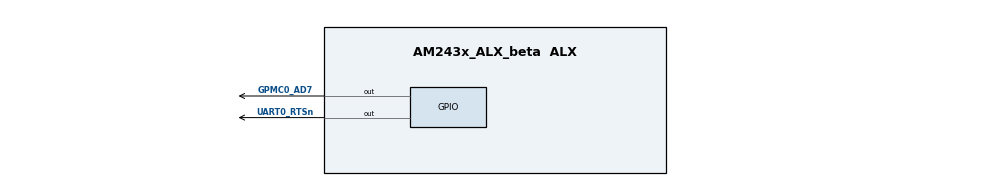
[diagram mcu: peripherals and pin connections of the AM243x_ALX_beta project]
/**
 * @cliArgs --device "AM243x_ALX_beta" --package "ALX" --part "ALX" --context "r5fss0-0" --product "MCU_PLUS_SDK@07.03.01"
 * @versions {"tool":"1.14.0+2667"}
 */

/**
 * Import the modules used in this configuration.
 */
const eeprom     = scripting.addModule("/board/eeprom/eeprom", {}, false);
const eeprom1    = eeprom.addInstance();
const flash      = scripting.addModule("/board/flash/flash", {}, false);
const flash1     = flash.addInstance();
const led        = scripting.addModule("/board/led/led", {}, false);
const led1       = led.addInstance();
const led2       = led.addInstance();
const led3       = led.addInstance();
const gpio       = scripting.addModule("/drivers/gpio/gpio", {}, false);
const gpio1      = gpio.addInstance();
const gpio2      = gpio.addInstance();
const i2c        = scripting.addModule("/drivers/i2c/i2c", {}, false);
const i2c1       = i2c.addInstance();
const pruicss    = scripting.addModule("/drivers/pruicss/pruicss", {}, false);
const pruicss1   = pruicss.addInstance();
const ethercat   = scripting.addModule("/industrial_comms/ethercat/ethercat", {}, false);
const ethercat1  = ethercat.addInstance();
const debug_log  = scripting.addModule("/kernel/dpl/debug_log");
const mpu_armv7  = scripting.addModule("/kernel/dpl/mpu_armv7", {}, false);
const mpu_armv71 = mpu_armv7.addInstance();
const mpu_armv72 = mpu_armv7.addInstance();
const mpu_armv73 = mpu_armv7.addInstance();
const mpu_armv74 = mpu_armv7.addInstance();

/**
 * Write custom configuration values to the imported modules.
 */
eeprom1.$name = "CONFIG_EEPROM0";

flash1.$name                              = "CONFIG_FLASH0";
flash1.peripheralDriver.$name             = "CONFIG_OSPI0";
flash1.peripheralDriver.OSPI.$assign      = "OSPI0";
flash1.peripheralDriver.OSPI.CLK.$assign  = "OSPI0_CLK";
flash1.peripheralDriver.OSPI.CSn0.$assign = "OSPI0_CSn0";
flash1.peripheralDriver.OSPI.D3.$assign   = "OSPI0_D3";
flash1.peripheralDriver.OSPI.D2.$assign   = "OSPI0_D2";
flash1.peripheralDriver.OSPI.D1.$assign   = "OSPI0_D1";
flash1.peripheralDriver.OSPI.D0.$assign   = "OSPI0_D0";

led1.$name = "CONFIG_LED_DIGITAL_OUTPUT";
led1.name  = "TPIC2810";

led2.$name = "CONFIG_LED_RUN";

led3.ioIndex = 16;
led3.$name   = "CONFIG_LED_ERROR";

gpio1.$name                = "CONFIG_GPIO0";
gpio1.pinDir               = "OUTPUT";
led2.peripheralDriver      = gpio1;
gpio1.GPIO.$assign         = "GPIO0";
gpio1.GPIO.gpioPin.$assign = "GPMC0_AD7";

gpio2.$name                = "CONFIG_GPIO1";
led3.peripheralDriver      = gpio2;
gpio2.GPIO.gpioPin.$assign = "UART0_RTSn";

led1.peripheralDriver    = i2c1;
i2c1.$name               = "CONFIG_I2C0";
eeprom1.peripheralDriver = i2c1;
i2c1.I2C.$assign         = "I2C0";
i2c1.I2C.SCL.$assign     = "I2C0_SCL";
i2c1.I2C.SDA.$assign     = "I2C0_SDA";

ethercat1.$name              = "CONFIG_ETHERCAT0";
ethercat1.instance           = "ICSSG1";
ethercat1.ethphy[0].$name    = "CONFIG_ETHPHY0";
ethercat1.ethphy[0].mdioPort = 3;
ethercat1.ethphy[1].$name    = "CONFIG_ETHPHY1";

ethercat1.icss                           = pruicss1;
pruicss1.$name                           = "CONFIG_PRU_ICSS1";
pruicss1.AdditionalICSSSettings[0].$name = "CONFIG_PRU_ICSS_IO0";

debug_log.enableUartLog            = true;
debug_log.enableCssLog             = false;
debug_log.uartLog.$name            = "CONFIG_UART0";
debug_log.uartLog.UART.$assign     = "USART0";
debug_log.uartLog.UART.RXD.$assign = "UART0_RXD";
debug_log.uartLog.UART.TXD.$assign = "UART0_TXD";

mpu_armv71.$name             = "CONFIG_MPU_REGION0";
mpu_armv71.size              = 31;
mpu_armv71.attributes        = "Device";
mpu_armv71.accessPermissions = "Supervisor RD+WR, User RD";
mpu_armv71.allowExecute      = false;

mpu_armv72.$name             = "CONFIG_MPU_REGION1";
mpu_armv72.size              = 15;
mpu_armv72.accessPermissions = "Supervisor RD+WR, User RD";

mpu_armv73.$name             = "CONFIG_MPU_REGION2";
mpu_armv73.baseAddr          = 0x41010000;
mpu_armv73.size              = 15;
mpu_armv73.accessPermissions = "Supervisor RD+WR, User RD";

mpu_armv74.$name             = "CONFIG_MPU_REGION3";
mpu_armv74.accessPermissions = "Supervisor RD+WR, User RD";
mpu_armv74.baseAddr          = 0x70000000;
mpu_armv74.size              = 21;

/**
 * Pinmux solution for unlocked pins/peripherals. This ensures that minor changes to the automatic solver in a future
 * version of the tool will not impact the pinmux you originally saw.  These lines can be completely deleted in order to
 * re-solve from scratch.
 */
gpio2.GPIO.$suggestSolution                                  = "GPIO1";
ethercat1.PRU_ICSSG1_MDIO.$suggestSolution                   = "PRU_ICSSG1_MDIO0";
ethercat1.PRU_ICSSG1_MDIO.MDC.$suggestSolution               = "PRG1_MDIO0_MDC";
ethercat1.PRU_ICSSG1_MDIO.MDIO.$suggestSolution              = "PRG1_MDIO0_MDIO";
ethercat1.PRU_ICSSG1_IEP.$suggestSolution                    = "PRU_ICSSG1_IEP0";
ethercat1.PRU_ICSSG1_IEP.EDC_LATCH_IN0.$suggestSolution      = "PRG1_PRU0_GPO18";
ethercat1.PRU_ICSSG1_IEP.EDC_LATCH_IN1.$suggestSolution      = "PRG1_PRU0_GPO7";
ethercat1.PRU_ICSSG1_IEP.EDC_SYNC_OUT0.$suggestSolution      = "PRG1_PRU0_GPO19";
ethercat1.PRU_ICSSG1_IEP.EDC_SYNC_OUT1.$suggestSolution      = "PRG1_PRU0_GPO17";
ethercat1.PRU_ICSSG1_IEP.EDIO_DATA_IN_OUT28.$suggestSolution = "PRG1_PRU0_GPO9";
ethercat1.PRU_ICSSG1_IEP.EDIO_DATA_IN_OUT29.$suggestSolution = "PRG1_PRU0_GPO10";
ethercat1.PRU_ICSSG1_IEP.EDIO_DATA_IN_OUT30.$suggestSolution = "PRG1_PRU1_GPO9";
ethercat1.PRU_ICSSG1_IEP.EDIO_DATA_IN_OUT31.$suggestSolution = "PRG1_PRU1_GPO10";
ethercat1.PRU_ICSSG1_MII_G_RT.$suggestSolution               = "PRU_ICSSG1_MII_G_RT";
ethercat1.PRU_ICSSG1_MII_G_RT.MII0_RXD0.$suggestSolution     = "PRG1_PRU0_GPO0";
ethercat1.PRU_ICSSG1_MII_G_RT.MII0_RXD1.$suggestSolution     = "PRG1_PRU0_GPO1";
ethercat1.PRU_ICSSG1_MII_G_RT.MII0_RXD2.$suggestSolution     = "PRG1_PRU0_GPO2";
ethercat1.PRU_ICSSG1_MII_G_RT.MII0_RXD3.$suggestSolution     = "PRG1_PRU0_GPO3";
ethercat1.PRU_ICSSG1_MII_G_RT.MII0_RXDV.$suggestSolution     = "PRG1_PRU0_GPO4";
ethercat1.PRU_ICSSG1_MII_G_RT.MII0_RXER.$suggestSolution     = "PRG1_PRU0_GPO5";
ethercat1.PRU_ICSSG1_MII_G_RT.MII0_RXLINK.$suggestSolution   = "PRG1_PRU0_GPO8";
ethercat1.PRU_ICSSG1_MII_G_RT.MII0_TXD0.$suggestSolution     = "PRG1_PRU0_GPO11";
ethercat1.PRU_ICSSG1_MII_G_RT.MII0_TXD1.$suggestSolution     = "PRG1_PRU0_GPO12";
ethercat1.PRU_ICSSG1_MII_G_RT.MII0_TXD2.$suggestSolution     = "PRG1_PRU0_GPO13";
ethercat1.PRU_ICSSG1_MII_G_RT.MII0_TXD3.$suggestSolution     = "PRG1_PRU0_GPO14";
ethercat1.PRU_ICSSG1_MII_G_RT.MII0_TXEN.$suggestSolution     = "PRG1_PRU0_GPO15";
ethercat1.PRU_ICSSG1_MII_G_RT.MII1_RXD0.$suggestSolution     = "PRG1_PRU1_GPO0";
ethercat1.PRU_ICSSG1_MII_G_RT.MII1_RXD1.$suggestSolution     = "PRG1_PRU1_GPO1";
ethercat1.PRU_ICSSG1_MII_G_RT.MII1_RXD2.$suggestSolution     = "PRG1_PRU1_GPO2";
ethercat1.PRU_ICSSG1_MII_G_RT.MII1_RXD3.$suggestSolution     = "PRG1_PRU1_GPO3";
ethercat1.PRU_ICSSG1_MII_G_RT.MII1_RXDV.$suggestSolution     = "PRG1_PRU1_GPO4";
ethercat1.PRU_ICSSG1_MII_G_RT.MII1_RXER.$suggestSolution     = "PRG1_PRU1_GPO5";
ethercat1.PRU_ICSSG1_MII_G_RT.MII1_RXLINK.$suggestSolution   = "PRG1_PRU1_GPO8";
ethercat1.PRU_ICSSG1_MII_G_RT.MII1_TXD0.$suggestSolution     = "PRG1_PRU1_GPO11";
ethercat1.PRU_ICSSG1_MII_G_RT.MII1_TXD1.$suggestSolution     = "PRG1_PRU1_GPO12";
ethercat1.PRU_ICSSG1_MII_G_RT.MII1_TXD2.$suggestSolution     = "PRG1_PRU1_GPO13";
ethercat1.PRU_ICSSG1_MII_G_RT.MII1_TXD3.$suggestSolution     = "PRG1_PRU1_GPO14";
ethercat1.PRU_ICSSG1_MII_G_RT.MII1_TXEN.$suggestSolution     = "PRG1_PRU1_GPO15";
ethercat1.PRU_ICSSG1_MII_G_RT.MII_MR0_CLK.$suggestSolution   = "PRG1_PRU0_GPO6";
ethercat1.PRU_ICSSG1_MII_G_RT.MII_MR1_CLK.$suggestSolution   = "PRG1_PRU1_GPO6";
ethercat1.PRU_ICSSG1_MII_G_RT.MII_MT0_CLK.$suggestSolution   = "PRG1_PRU0_GPO16";
ethercat1.PRU_ICSSG1_MII_G_RT.MII_MT1_CLK.$suggestSolution   = "PRG1_PRU1_GPO16";
